# R7FA6M5BH register map
Vendor: Renesas Electronics Corporation; Series: RA6; File version: 1.20.01
CPU: CM33 r0p4, little endian, MPU, FPU, VTOR, 4 interrupt priority bits, 96 interrupts
Registers are 32-bit, read-write, reset 0x0 unless marked. A register's access mark holds for its fields unless they carry their own. Offsets are from the block's base; [hi:lo] are bit positions; {n}, {i} and the like mark numbered series; 'fields as' and 'values as' point back to an identical list.

## USBHS — USB 2.0 High-Speed Module
Base 0x40111000
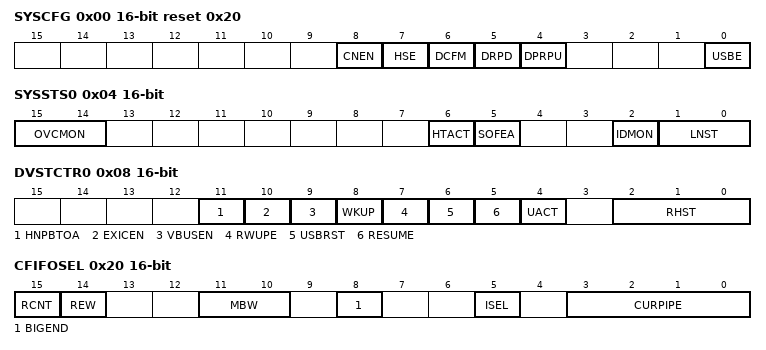
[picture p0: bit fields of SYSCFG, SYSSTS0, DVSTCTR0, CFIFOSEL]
0x00 SYSCFG 16-bit reset 0x20 — System Configuration Control Register
  [8] CNEN — Single-ended Receiver Enable
    0=Disable; 1=Enable
  [7] HSE — High-Speed Operation Enable
    0=Disable Device controller mode: full-speed Host controller mode: full- or low-speed; 1=Enable The controller detects the communication speed
  [6] DCFM — Controller Operation Select
    0=Select device controller mode; 1=Select host controller mode
  [5] DRPD — D+/D- Line Resistor Control
    0=Disable line pull-down; 1=Enable line pull-down
  [4] DPRPU — D+ Line Resistor Control
    0=Disable line pull-up; 1=Enable line pull-up
  [0] USBE — USBHS Operation Enable
    0=Disable; 1=Enable
0x02 BUSWAIT 16-bit reset 0xF — CPU Bus Wait Register
  [3:0] BWAIT — CPU Bus Access Wait Specification
0x04 SYSSTS0 16-bit ro (reset mask 0x60) — System Configuration Status Register
  [15:14] OVCMON — External USBHS_OVRCURA/USBHS_O VRCURB Input Pin Monitor Flag
  [6] HTACT — Host Sequencer Status Monitor Flag
    0=Host sequencer stopped; 1=Host sequencer operating
  [5] SOFEA — SOF Active Monitor Flag While Host Controller Operation Is Selected
    0=SOF output stopped; 1=SOF output operating
  [2] IDMON — USBHS_ID Pin Monitor Flag
    0=USBHS_ID pin is low; 1=USBHS_ID pin is high
  [1:0] LNST — USB Data Line Status Monitor Flag
0x06 PLLSTA 16-bit ro — PLL Status Register
  [0] PLLLOCK — PLL Lock Flag
    0=PLL not locked; 1=PLL locked
0x08 DVSTCTR0 16-bit — Device State Control Register 0
  [11] HNPBTOA — Host Negotiation Protocol (HNP) Control
  [10] EXICEN — USBHS_EXICEN Output Pin Control
    0=Output low on external USBHS_EXICEN pin; 1=Output high on external USBHS_EXICEN pin
  [9] VBUSEN — USBHS_VBUSEN Output Pin Control
    0=Output low on external USBHS_VBUSEN pin; 1=Output high on external USBHS_VBUSEN pin
  [8] WKUP — Remote Wakeup Output for the Device Controller Operation
    0=Do not output remote wakeup signal; 1=Output remote wakeup signal
  [7] RWUPE — Remote Wakeup Detection Enable for the Host Controller Operation
    0=Disable downstream port remote wakeup; 1=Enable downstream port remote wakeup
  [6] USBRST — USB Bus Reset Output for the Host Controller Operation
    0=Do not output USB bus reset signal; 1=Output USB bus reset signal
  [5] RESUME — Resume Signal Output for the Host Controller Operation
    0=Do not output resume signal; 1=Output resume signal
  [4] UACT — USB Bus Operation Enable for the Host Controller Operation
    0=Disable downstream port (disable SOF or micro-SOF transmission); 1=Enable downstream port (enable SOF or micro-SOF transmission)
  [2:0] RHST ro — USB Bus Reset Status Flag
    0=Communication speed indeterminate (powered state or no connection); 1=Host controller mode Low-speed connection Device controller mode USB bus reset in progress or low-speed connection; 2=Host controller mode Full-speed connection Device controller mode USB bus reset in progress or full-speed connection; 3=Host controller mode High-speed connection Device controller mode USB bus reset in progress or high-speed connection; other=Others (Host controller mode USB bus reset in progress Device controller mode Setting prohibited)
0x0C TESTMODE 16-bit — USB Test Mode Register
  [3:0] UTST — Test Mode
0x14 CFIFO — FIFO Port Register
  [31:0] FIFOPORT — Read receive data from the FIFO buffer or write transmit data to the FIFO buffer by accessing these bits.
0x14 CFIFOL 16-bit (alternate view of CFIFO) — FIFO Port Register
0x14 CFIFOLL 8-bit (alternate view of CFIFO) — FIFO Port Register
0x16 CFIFOH 16-bit (alternate view of CFIFO) — FIFO Port Register
  [15:0] FIFOPORT — Read receive data from the FIFO buffer or write transmit data to the FIFO buffer by accessing these bits.
0x17 CFIFOHH 8-bit (alternate view of CFIFO) — FIFO Port Register
  [7:0] FIFOPORT — Read receive data from the FIFO buffer or write transmit data to the FIFO buffer by accessing these bits.
0x18 D0FIFO — FIFO Port Register
  fields as CFIFO
0x18 D1FIFO (alternate view of D0FIFO) — FIFO Port Register
  fields as CFIFO
0x18 D0FIFOL 16-bit (alternate view of D0FIFO) — FIFO Port Register
0x18 D1FIFOL 16-bit (alternate view of D0FIFO) — FIFO Port Register
0x18 D0FIFOLL 8-bit (alternate view of D0FIFO) — FIFO Port Register
0x18 D1FIFOLL 8-bit (alternate view of D0FIFO) — FIFO Port Register
0x1A D0FIFOH 16-bit (alternate view of D0FIFO) — FIFO Port Register
  fields as CFIFOH
0x1A D1FIFOH 16-bit (alternate view of D0FIFOH) — FIFO Port Register
  fields as CFIFOH
0x1B D0FIFOHH 8-bit (alternate view of D0FIFO) — FIFO Port Register
  fields as CFIFOHH
0x1B D1FIFOHH 8-bit (alternate view of D0FIFOHH) — FIFO Port Register
  fields as CFIFOHH
0x20 CFIFOSEL 16-bit — CFIFO Port Selection Register
  [15] RCNT — Read Count Mode
    0=Clear DTLN[11:0] flags in the FIFO port control register to 0x000 when all receive data is read from CFIFO; 1=Decrement DTLN[11:0] flags each time receive data is read from CFIFO
  [14] REW wo — Buffer Pointer Rewind
    0=Do not rewind buffer pointer (Writing 0 has no effect.); 1=Rewind buffer pointer
  [11:10] MBW — CFIFO Port Access Bit Width
    0=8-bit width; 1=16-bit width; 2=32-bit width; 3=Setting prohibited
  [8] BIGEND — FIFO Port Endian Control
    0=Little endian; 1=Big endian
  [5] ISEL — FIFO Port Access Direction when DCP Is Selected
    0=Select reading from the FIFO buffer; 1=Select writing to the FIFO buffer
  [3:0] CURPIPE — FIFO Port Access Pipe Specification
    0=DCP (default control pipe); {v}=Pipe {v} (v=1..9); other=Others (Setting prohibited)
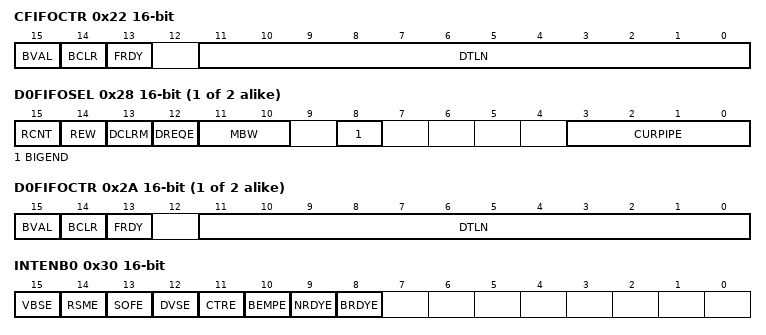
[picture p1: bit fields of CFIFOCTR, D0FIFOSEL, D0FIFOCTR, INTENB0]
0x22 CFIFOCTR 16-bit — FIFO Port Control Register
  [15] BVAL — FIFO Buffer Valid Flag
    0=Invalid (writing 0 has no effect); 1=Writing ended
  [14] BCLR wo — CPU Buffer Clear
    0=No operation (writing 0 has no effect); 1=Clear FIFO buffer on the CPU side
  [13] FRDY ro — FIFO Port Ready Flag
    0=FIFO port access disabled; 1=FIFO port access enabled
  [11:0] DTLN ro — Receive Data Length Flag
{0x28+4i} D{i}FIFOSEL (i=0..1) 16-bit — D{i}FIFO Port Selection Register
  [15] RCNT — Read Count Mode
    0=Clear DTLN[11:0] flags in the FIFO port control register to 0x000 when all receive data is read from DnFIFO (after read of a single plane in double buffer mode); 1=Decrement DTLN[11:0] flags each time receive data is read from DnFIFO
  [14] REW wo — Buffer Pointer Rewind
    0=Do not rewind buffer pointer (writing 0 has no effect); 1=Rewind buffer pointer
  [13] DCLRM — Auto FIFO Buffer Clear Mode after Specified Pipe is Read
    0=Disable auto buffer clear mode; 1=Enable auto buffer clear mode
  [12] DREQE — DMA/DTC Transfer Request Enable
    0=Disable DMA/DTC transfer request; 1=Enable DMA/DTC transfer request
  [11:10] MBW — FIFO Port Access Bit Width
    values as CFIFOSEL.MBW
  [8] BIGEND — FIFO Port Endian Control
    0=Little endian; 1=Big endian
  [3:0] CURPIPE — FIFO Port Access Pipe Specification
    0=No pipe specification; {v}=Pipe {v} (v=1..9); other=Others (Setting prohibited)
{0x2A+4i} D{i}FIFOCTR (i=0..1) 16-bit — FIFO Port Control Register
  fields as CFIFOCTR
0x30 INTENB0 16-bit — Interrupt Enable Register 0
  [all] fields
    0=Disable interrupt request; 1=Enable interrupt request
  [15] VBSE — VBUS Interrupt Request Enable
  [14] RSME — Resume Interrupt Request Enable
  [13] SOFE — Frame Number Update Interrupt Request Enable
  [12] DVSE — Device State Transition Interrupt Request Enable
  [11] CTRE — Control Transfer Stage Transition Interrupt Request Enable
  [10] BEMPE — Buffer Empty Interrupt Request Enable
  [9] NRDYE — Buffer Not Ready Response Interrupt Request Enable
  [8] BRDYE — Buffer Ready Interrupt Request Enable
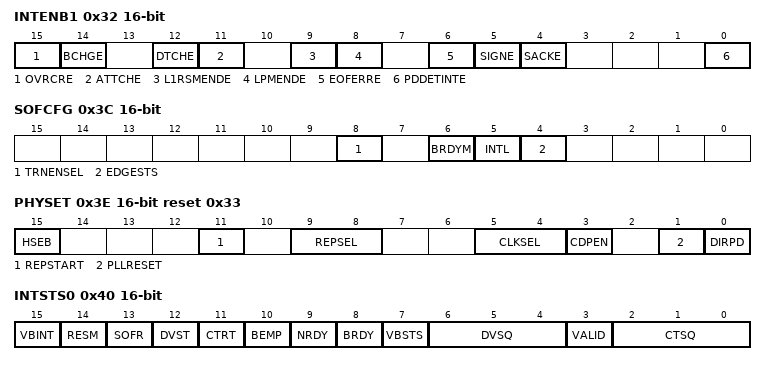
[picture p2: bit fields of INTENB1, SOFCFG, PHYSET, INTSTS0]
0x32 INTENB1 16-bit — Interrupt Enable Register 1
  [all] fields
    0=Disable interrupt request; 1=Enable interrupt request
  [15] OVRCRE — OVRCRE Interrupt Request Enable
  [14] BCHGE — USB Bus Change Interrupt Request Enable
  [12] DTCHE — Disconnection Detection Interrupt Request Enable
  [11] ATTCHE — Connection Detection Interrupt Request Enable
  [9] L1RSMENDE — L1 Resume End Interrupt Enable
  [8] LPMENDE — LPM Transaction End Interrupt Request Enable
  [6] EOFERRE — EOF Error Detection Interrupt Request Enable
  [5] SIGNE — Setup Transaction Error Interrupt Request Enable
  [4] SACKE — Setup Transaction Normal Response Interrupt Request Enable
  [0] PDDETINTE — PDDETINT Detection Interrupt Request Enable
0x36 BRDYENB 16-bit — BRDY Interrupt Enable Register
  [9:0] PIPEBRDYE — BRDY Interrupt Request Enable for Pipes [9:0]
    0=Disable interrupt request; 1=Enable interrupt request
0x38 NRDYENB 16-bit — NRDY Interrupt Enable Register
  [9:0] PIPENRDYE — NRDY Interrupt Enable for Pipes [9:0]
    0=Disable interrupt request; 1=Enable interrupt request
0x3A BEMPENB 16-bit — BEMP Interrupt Enable Register
  [9:0] PIPEBEMPE — BEMP Interrupt Enable for Pipes [9:0]
    0=Disable interrupt request; 1=Enable interrupt request
0x3C SOFCFG 16-bit — SOF Output Configuration Register
  [8] TRNENSEL — Transaction-Enabled Time Select
    0=Not low-speed communication; 1=Low-speed communication
  [6] BRDYM — PIPEBRDY Interrupt Status Clear Timing
    0=Clear BRDY flag through software; 1=Clear BRDY flag by the USBHS through a data read from the FIFO buffer or data write to the FIFO buffer
  [5] INTL — Interrupt Output Sense Select
    0=Edge detection; 1=Level detection
  [4] EDGESTS ro — Interrupt Edge Processing Status Flag
0x3E PHYSET 16-bit reset 0x33 (reset mask 0xB3B) — PHY Setting Register
  [15] HSEB — CL-only mode
    0=Disable CL-only mode; 1=Enable CL-only mode
  [11] REPSTART — Forcibly Start Terminating Resistance Adjustment
    0=Force terminating resistance adjustment to start; 1=Do not force terminating resistance adjustment to start
  [9:8] REPSEL — Terminating Resistance Adjustment Cycle
    0=No cycle is set; 1=Adjust terminating resistance at 16-second intervals; 2=Adjust terminating resistance at 64-second intervals; 3=Adjust terminating resistance at 128-second intervals
  [5:4] CLKSEL — Input System Clock Frequency
    0=12 MHz; 1=Setting prohibited; 2=20 MHz; 3=24 MHz
  [3] CDPEN — Charging Downstream Port Enable
    0=Disable downstream port charging; 1=Enable downstream port charging
  [1] PLLRESET — PLL Reset Control
    0=Disable PLL reset control for UTMI_PHY; 1=Enable PLL reset control for UTMI_PHY
  [0] DIRPD — Power-Down Control
    0=Do not enter low power mode; 1=Enter low power mode
0x40 INTSTS0 16-bit (reset mask 0xFF7F) — Interrupt Status Register 0
  [15] VBINT — VBUS Interrupt Status Flag
    0=No VBUS interrupt occurred on detecting a change in the USBHS_VBUS pin; 1=VBUS interrupt occurred on detecting a change in the USBHS_VBUS pin
  [14] RESM — Resume Interrupt Status Flag
    0=No resume interrupt occurred; 1=Resume interrupt occurred
  [13] SOFR — Frame Number Refresh Interrupt Status Flag
    0=No SOF interrupt occurred; 1=SOF interrupt occurred
  [12] DVST — Device State Transition Interrupt Status Flag
    0=No device state transition interrupt occurred; 1=Device state transition interrupt occurred
  [11] CTRT — Control Transfer Stage Transition Interrupt Status Flag
    0=No control transfer stage transition interrupt occurred; 1=Control transfer stage transition interrupt occurred
  [10] BEMP ro — BEMP Interrupt Status Flag
    0=No BEMP interrupt occurred; 1=BEMP interrupt occurred
  [9] NRDY ro — NRDY Interrupt Status Flag
    0=No NRDY interrupt occurred; 1=NRDY interrupt occurred
  [8] BRDY ro — BRDY Interrupt Status Flag
    0=No BRDY interrupt occurred; 1=BRDY interrupt occurred
  [7] VBSTS ro — VBUS Input Status Flag
    0=USBHS_VBUS pin is low; 1=USBHS_VBUS pin is high
  [6:4] DVSQ ro — Device State
    0=Powered state; 1=Default state; 2=Address state; 3=Configured state; other=Others (Suspend state)
  [3] VALID — USB Request Reception Flag
    0=Setup packet not received; 1=Setup packet received
  [2:0] CTSQ ro — Control Transfer Stage Flag
    0=Idle or setup stage; 1=Control read data stage; 2=Control read status stage; 3=Control write data stage; 4=Control write status stage; 5=Control write (no data) status stage; 6=Control transfer sequence error
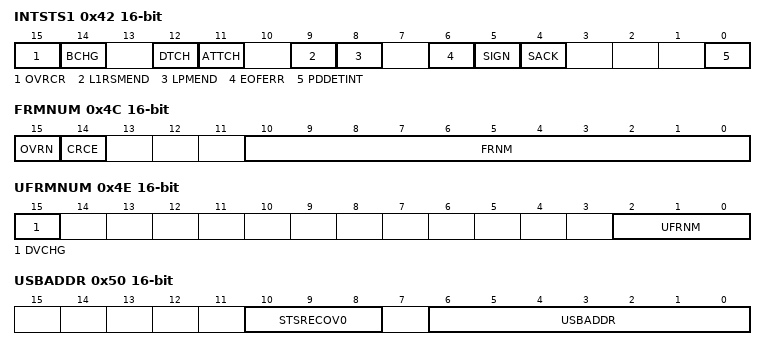
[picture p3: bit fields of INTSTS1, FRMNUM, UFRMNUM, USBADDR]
0x42 INTSTS1 16-bit — Interrupt Status Register 1
  [15] OVRCR — OVRCR Interrupt Status Flag
    0=No OVRCR interrupt occurred; 1=OVRCR interrupt occurred
  [14] BCHG — USB Bus Change Interrupt Status Flag
    0=No BCHG interrupt occurred; 1=BCHG interrupt occurred
  [12] DTCH — USB Disconnection Detection Interrupt Status Flag
    0=No DTCH interrupt occurred; 1=DTCH interrupt occurred
  [11] ATTCH — USB Connection Detection Interrupt Status Flag
    0=No ATTCH interrupt occurred; 1=ATTCH interrupt occurred
  [9] L1RSMEND — L1 Resume End Interrupt Status Flag
    0=No L1RSMEND interrupt occurred; 1=L1RSMEND interrupt occurred
  [8] LPMEND — LPM Transaction End Interrupt Status Flag
    0=No LPMEND interrupt occurred; 1=LPMEND interrupt occurred
  [6] EOFERR — EOF Error Detection Interrupt Status Flag
    0=No EOFERR interrupt occurred; 1=EOFERR interrupt occurred
  [5] SIGN — Setup Transaction Error Interrupt Status Flag
    0=No SIGN interrupt occurred; 1=SIGN interrupt occurred
  [4] SACK — Setup Transaction Normal Response Interrupt Status Flag
    0=No SACK interrupt occurred; 1=SACK interrupt occurred
  [0] PDDETINT — PDDET Detection Interrupt Status Flag
    0=No PDDET interrupt occurred; 1=PDDET interrupt occurred
0x46 BRDYSTS 16-bit — BRDY Interrupt Status Register
  [9:0] PIPEBRDY — BRDY Interrupt Status Flag for Pipe[9:0]
    0=No BRDY interrupt occurred; 1=BRDY interrupt occurred
0x48 NRDYSTS 16-bit — NRDY Interrupt Status Register
  [9:0] PIPENRDY — NRDY Interrupt Status Flag for Pipe[9:0]
    0=No NRDY interrupt occurred; 1=NRDY interrupt occurred
0x4A BEMPSTS 16-bit — BEMP Interrupt Status Register
  [9:0] PIPEBEMP — BEMP Interrupt Status Flag for Pipe[9:0]
    0=No BEMP interrupt occurred; 1=BEMP interrupt occurred
0x4C FRMNUM 16-bit — Frame Number Register
  [15] OVRN — Overrun/Underrun Detection Status Flag
    0=No error occurred; 1=Error occurred
  [14] CRCE — CRC Error Detection Status Flag
    0=No error occurred; 1=Error occurred
  [10:0] FRNM ro — Frame Number Flag
0x4E UFRMNUM 16-bit — µFrame Number Register
  [15] DVCHG — Device State Change
    0=Disable writes to the USBADDR.STSRECOV0[2:0] and USBADDR.USBADDR[6:0] bits; 1=Enable writes to the USBADDR.STSRECOV0[2:0] and USBADDR.USBADDR[6:0] bits
  [2:0] UFRNM ro — Microframe number
0x50 USBADDR 16-bit — USB Address Register
  [10:8] STSRECOV0 — Status Recovery
    1=[D] Return to the full-speed connection and Default state; 2=[D] Return to the full-speed connection and Address state [H] Return to the low-speed state (bits DVSTCTR0.RHST[2:0] = 001b); 3=[D] Return to the full-speed connection and Configured state; 4=[D] Return to the suspend connection and Suspend state [H] Return to the full-speed state (bits DVSTCTR0.RHST[2:0] = 010b); 5=[D] Return to the high-speed connection and Default state; 6=[D] Return to the high-speed connection and Address state [H] Return to the high-speed state (bits DVSTCTR0.RHST[2:0] = 011b); 7=[D] Return to the high-speed connection and Configured state
  [6:0] USBADDR ro — USB Address Flag
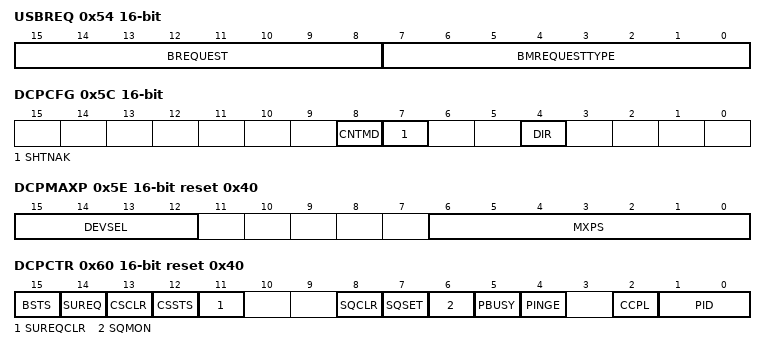
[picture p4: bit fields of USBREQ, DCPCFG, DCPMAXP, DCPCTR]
0x54 USBREQ 16-bit — USB Request Type Register
  [15:8] BREQUEST — USB request bRequest value
  [7:0] BMREQUESTTYPE — USB request bmRequestType value
0x56 USBVAL 16-bit — USB Request Value Register
  [15:0] WVALUE — USB request wValue value
0x58 USBINDX 16-bit — USB Request Index Register
  [15:0] WINDEX — USB request wIndex value
0x5A USBLENG 16-bit — USB Request Length Register
  [15:0] WLENTUH — USB request wLength value
0x5C DCPCFG 16-bit — DCP Configuration Register
  [8] CNTMD — Continuous Transfer Mode
    0=Non-continuous transfer mode; 1=Continuous transfer mode
  [7] SHTNAK — Pipe Blocking on End of Transfer
    0=Keep pipe open after transfer ends; 1=Disable pipe after transfer ends
  [4] DIR — Transfer Direction
    0=Data receiving direction; 1=Data transmitting direction
0x5E DCPMAXP 16-bit reset 0x40 — DCP Maximum Packet Size Register
  [15:12] DEVSEL — Device Select
    {v}=Address {0x0+v} (v=0..5)
  [6:0] MXPS — Maximum Packet Size
0x60 DCPCTR 16-bit reset 0x40 (reset mask 0xF1F7) — DCP Control Register
  [15] BSTS ro — Buffer Status Flag
    0=Buffer access disabled; 1=Buffer access enabled
  [14] SUREQ — SETUP Token Transmission
    0=Invalid (writing 0 has no effect); 1=Transmit setup packet
  [13] CSCLR wo — CSSTS Status Flag Clear
    0=(writing 0 has no effect); 1=Clear CSSTS to 0
  [12] CSSTS ro — CSSTS Status Flag
    0=Start-split (SSPLIT) transaction, or processing for devices that are not using split transactions, in progress; 1=Complete-split (CSPLIT) transaction in progress
  [11] SUREQCLR wo — SUREQ Bit Clear
    0=Invalid (writing 0 has no effect); 1=Clear SUREQ to 0
  [8] SQCLR wo — Sequence Toggle Bit Clear
    0=Invalid (writing 0 has no effect); 1=Clear the expected value for the next transaction to DATA0
  [7] SQSET wo — Sequence Toggle Bit Set
    0=Invalid (writing 0 has no effect); 1=Set the expected value for the next transaction to DATA1
  [6] SQMON ro — Sequence Toggle Bit Monitor Flag
    0=DATA0; 1=DATA1
  [5] PBUSY ro — Pipe Busy Flag
    0=DCP not used for the USB bus; 1=DCP in use for the USB bus
  [4] PINGE — PING Token Issue Enable
    0=Disable PING token; 1=Enable normal PING operation
  [2] CCPL — Control Transfer End Enable
    0=Disable control transfer completion; 1=Enable control transfer completion
  [1:0] PID — Response PID
    0=NAK response; 1=BUF response (depends on buffer state); 2=STALL response; 2=STALL response
0x64 PIPESEL 16-bit — Pipe Window Select Register
  [3:0] PIPESEL — Pipe Window Select
    0=No pipe selected; {v}=Pipe {v} (v=1..9); other=Others (Setting prohibited)
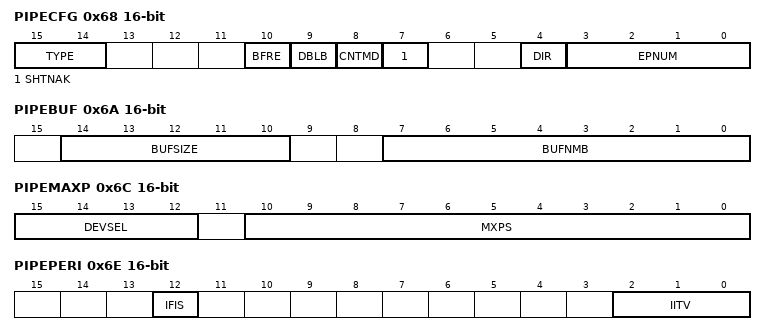
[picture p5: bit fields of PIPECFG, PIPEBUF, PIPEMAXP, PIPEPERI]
0x68 PIPECFG 16-bit — Pipe Configuration Register
  [15:14] TYPE — Transfer Type
    0=Pipe not used; 1=(Pipe 1 to 5) Bulk transfer (Pipe 6 to 9) Setting prohibited; 2=(Pipe 1 to 5) Setting prohibited (Pipe 6 to 9) Interrupt transfer; 3=(Pipe 1 to 2) Isochronous transfer (Pipe 3 to 9) Setting prohibited
  [10] BFRE — BRDY Interrupt Operation Specification
    0=Generate BRDY interrupt on transmitting or receiving data; 1=Generate BRDY interrupt on completion of reading data
  [9] DBLB — Double Buffer Mode
    0=Single buffer; 1=Double buffer
  [8] CNTMD — Continuous Transfer Mode
    0=Discontinuous transfer mode; 1=Continuous transfer mode
  [7] SHTNAK — Pipe Disabled at End of Transfer
    0=Continue pipe operation after transfer ends; 1=Disable pipe after transfer ends
  [4] DIR — Transfer Direction
    0=Receiving direction; 1=Transmitting direction
  [3:0] EPNUM — Endpoint Number
0x6A PIPEBUF 16-bit — Pipe Buffer Register
  [14:10] BUFSIZE — Buffer Size
  [7:0] BUFNMB — Buffer Number
0x6C PIPEMAXP 16-bit (reset mask 0xEFFF) — Pipe Maximum Packet Size Register
  [15:12] DEVSEL — Device Select
  [10:0] MXPS — Maximum Packet Size
0x6E PIPEPERI 16-bit — Pipe Cycle Control Register
  [12] IFIS — Isochronous IN Buffer Flush
    0=Do not flush buffer; 1=Flush buffer
  [2:0] IITV — Interval Error Detection Interval
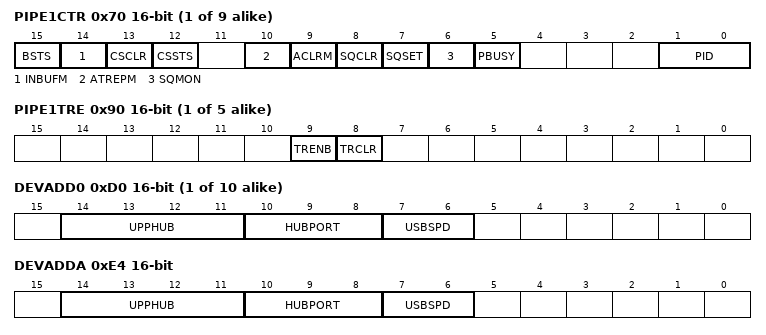
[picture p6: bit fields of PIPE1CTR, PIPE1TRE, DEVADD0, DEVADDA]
{0x6C+4i} PIPE{i}CTR (i=1..9) 16-bit — Pipe {i} Control Register
  [15] BSTS ro — Buffer Status Flag
    0=Buffer access disabled; 1=Buffer access enabled
  [14] INBUFM ro — Transmit Buffer Monitor Flag
    0=No data to be transmitted is in the FIFO buffer; 1=Data to be transmitted is in the FIFO buffer
  [13] CSCLR wo — CSPLIT Status Clear
    0=Invalid (writing 0 has no effect); 1=Clear CSSTS to 0
  [12] CSSTS ro — CSSTS Status Flag
    values as DCPCTR.CSSTS
  [10] ATREPM — Auto Response Mode
    0=Disable auto response mode; 1=Enable auto response mode
  [9] ACLRM — Auto Buffer Clear Mode
    0=Disable; 1=Enable (initialize all buffers)
  [8] SQCLR wo — Sequence Toggle Bit Clear
    values as DCPCTR.SQCLR
  [7] SQSET — Sequence Toggle Bit Set
    0=Invalid (writing 0 has no effect); 1=Set the expected value for the next transaction to DATA1. This bit is read as 0.
  [6] SQMON ro — Sequence Toggle Bit Monitor Flag
    0=DATA0; 1=DATA1
  [5] PBUSY ro — Pipe Busy Flag
    0=Pipe n not in use for the transaction; 1=Pipe n in use for the transaction
  [1:0] PID — Response PID
    0=NAK response; 1=BUF response (depends on buffer state); 2=STALL response; 3=STALL response
{0x8C+4i} PIPE{i}TRE (i=1..5) 16-bit — Pipe {i} Transaction Counter Enable Register
  [9] TRENB — Transaction Counter Enable
    0=Disable transaction counter; 1=Enable transaction counter
  [8] TRCLR — Transaction Counter Clear
    0=Invalid (writing 0 has no effect); 1=Clear current counter value
{0x8E+4i} PIPE{i}TRN (i=1..5) 16-bit — Pipe {i} Transaction Counter Register
  [15:0] TRNCNT — Transaction Counter
{0xD0+2i} DEVADD{i} (i=0..9) 16-bit — Device Address {i} Configuration Register
  [14:11] UPPHUB — Communication Target Connecting Hub Register
    0=Connect directly to the USBHS port; other=Others (USB address of the hub. The value as 0xB or more is reserved.)
  [10:8] HUBPORT — Communication Target Connecting Hub Port
    0=Connect directly to the USBHS port; other=Others (Port number of the hub)
  [7:6] USBSPD — Transfer Speed of Communication Target Device
    0=Do not use DEVADDm; 1=Low speed; 2=Full speed; 3=High speed
0xE4 DEVADDA 16-bit — Device Address A Configuration Register
  fields as DEVADD0
0x100 LPCTRL 16-bit — Low Power Control Register
  [7] HWUPM — Resume Return Mode Setting
    0=Hardware does not recover while CPU clock inactive; 1=Hardware recovers while CPU clock inactive
0x102 LPSTS 16-bit — Low Power Status Register
  [14] SUSPENDM — UTMI SuspendM Control
    0=UTMI suspension mode; 1=UTMI normal mode
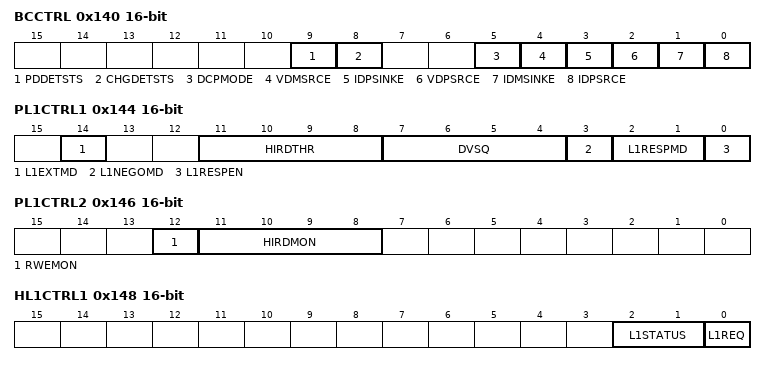
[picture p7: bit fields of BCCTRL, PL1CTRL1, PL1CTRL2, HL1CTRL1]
0x140 BCCTRL 16-bit — Battery Charging Control Register
  [9] PDDETSTS ro — PDDET Status Flag
    0=The PDDET pin is at low level; 1=The PDDET pin is at high level
  [8] CHGDETSTS ro — CHGDET Status Flag
    0=The CHGDET pin is at low level; 1=The CHGDET pin is at high level
  [5] DCPMODE — DCP Mode Control
    0=Disable RDCP_DAT resistor; 1=Enable RDCP_DAT resistor
  [4] VDMSRCE — VDMSRC Control
    0=Disable VDM_SRC circuit; 1=Enable VDM_SRC circuit
  [3] IDPSINKE — IDPSINK Control
    0=Disable IDP_SINK circuit; 1=Enable IDP_SINK circuit
  [2] VDPSRCE — VDPSRC Control
    0=Disable VDP_SRC circuit; 1=Enable VDP_SRC circuit
  [1] IDMSINKE — IDMSINK Control
    0=Disable IDM_SINK circuit; 1=Enable IDM_SINK circuit
  [0] IDPSRCE — IDPSRC Control
    0=Disable IDP_SRC circuit; 1=Enable IDP_SRC circuit
0x144 PL1CTRL1 16-bit — Function L1 Control Register 1
  [14] L1EXTMD — PHY Control Mode at L1 Return
    0=Do not set LPSTS.SUSPENDM bit through hardware when Host K is received; 1=Set LPSTS.SUSPENDM bit through hardware when Host K is received
  [11:8] HIRDTHR — L1 Response Negotiation Threshold Value
  [7:4] DVSQ ro — DVSQ Extension Flag
    0=Powered state; 1=Default state; 2=Address state; 3=Configured state; 0b01xx=Suspend state; 0b10xx=L1 state
  [3] L1NEGOMD — L1 Response Negotiation Control
    0=Return ACK when received HIRD is larger than HIRDTHR[3:0]. Otherwise (including when HIRD = HIRDTHR[3:0]), return NYET; 1=Return ACK when received HIRD is smaller than HIRDTHR[3:0]. Otherwise (including when HIRD = HIRDTHR[3:0]), return NYET
  [2:1] L1RESPMD — L1 Response Mode
    0=NYET response; 1=ACK response; 2=STALL response; 3=Response based on L1NEGOMD setting
  [0] L1RESPEN — L1 Response Enable
    0=Do not support LPM; 1=Support LPM
0x146 PL1CTRL2 16-bit — Function L1 Control Register 2
  [12] RWEMON ro — RWE Value Monitor
  [11:8] HIRDMON ro — HIRD Value Monitor
0x148 HL1CTRL1 16-bit — Host L1 Control Register 1
  [2:1] L1STATUS ro — L1 Request Completion Status
    0=ACK received; 1=NYET received; 2=STALL received; 3=Transaction error
  [0] L1REQ — L1 Transition Request
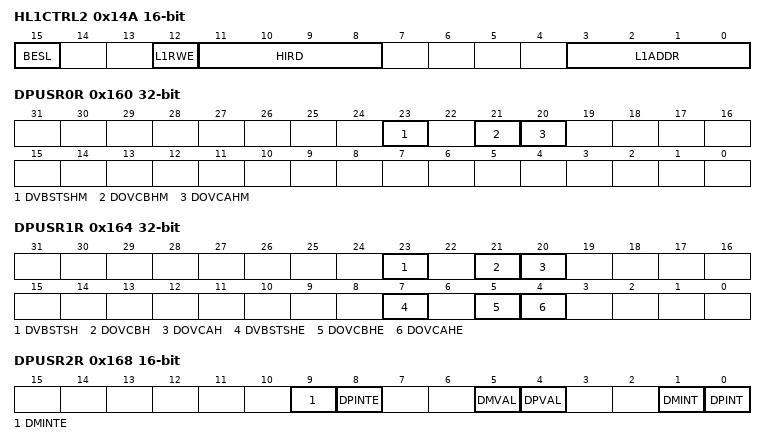
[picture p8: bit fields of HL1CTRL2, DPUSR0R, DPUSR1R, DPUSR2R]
0x14A HL1CTRL2 16-bit — Host L1 Control Register 2
  [15] BESL — BESL & Alternate HIRD
  [12] L1RWE — LPM Token L1 RemoteWake Enable
  [11:8] HIRD — LPM Token HIRD
  [3:0] L1ADDR — LPM Token DeviceAddress
0x160 DPUSR0R ro (reset mask 0xFF4FFFFF) — Deep Software Standby USB Transceiver Control/Pin Monitor Register
  [23] DVBSTSHM — VBUS Input Flag
  [21] DOVCBHM — OVRCURB Input Flag
  [20] DOVCAHM — OVRCURA Input Flag
0x164 DPUSR1R — Deep Software Standby USB Suspend/Resume Interrupt Register
  [23] DVBSTSH ro — VBUS Interrupt Source Return Status Flag
    0=System has not recovered from Deep Software Standby mode; 1=System recovered from Deep Software Standby mode
  [21] DOVCBH ro — OVRCURB Interrupt Source Return Status Flag
    values as DVBSTSH
  [20] DOVCAH ro — OVRCURA Interrupt Source Return Status Flag
    values as DVBSTSH
  [7] DVBSTSHE — VBUS Interrupt Enable/Clear
    0=Disable recovery from Deep Software Standby mode; 1=Enable recovery from Deep Software Standby mode
  [5] DOVCBHE — OVRCURB Interrupt Enable Clear
    values as DVBSTSHE
  [4] DOVCAHE — OVRCURA Interrupt Enable Clear
    values as DVBSTSHE
0x168 DPUSR2R 16-bit — Deep Software Standby USB Suspend/Resume Interrupt Register
  [9] DMINTE — DM Interrupt Enable Clear
    values as DPUSR1R.DVBSTSHE
  [8] DPINTE — DP Interrupt Enable Clear
    values as DPUSR1R.DVBSTSHE
  [5] DMVAL ro — DM Input
  [4] DPVAL ro — DP Input
  [1] DMINT ro — Indication of Return from DM Interrupt Source
    values as DPUSR1R.DVBSTSH
  [0] DPINT ro — Indication of Return from DP Interrupt Source
    values as DPUSR1R.DVBSTSH
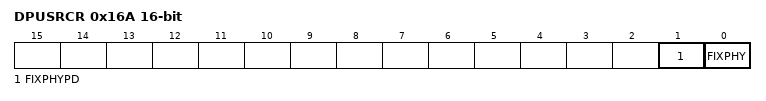
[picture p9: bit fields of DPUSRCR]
0x16A DPUSRCR 16-bit — Deep Software Standby USB Suspend/Resume Command Register
  [1] FIXPHYPD — USB Transceiver Control Fix for PLL
    0=Normal mode; 1=Invoke/recover from Deep Software Standby mode
  [0] FIXPHY — USB Transceiver Control Fix
    values as FIXPHYPD
